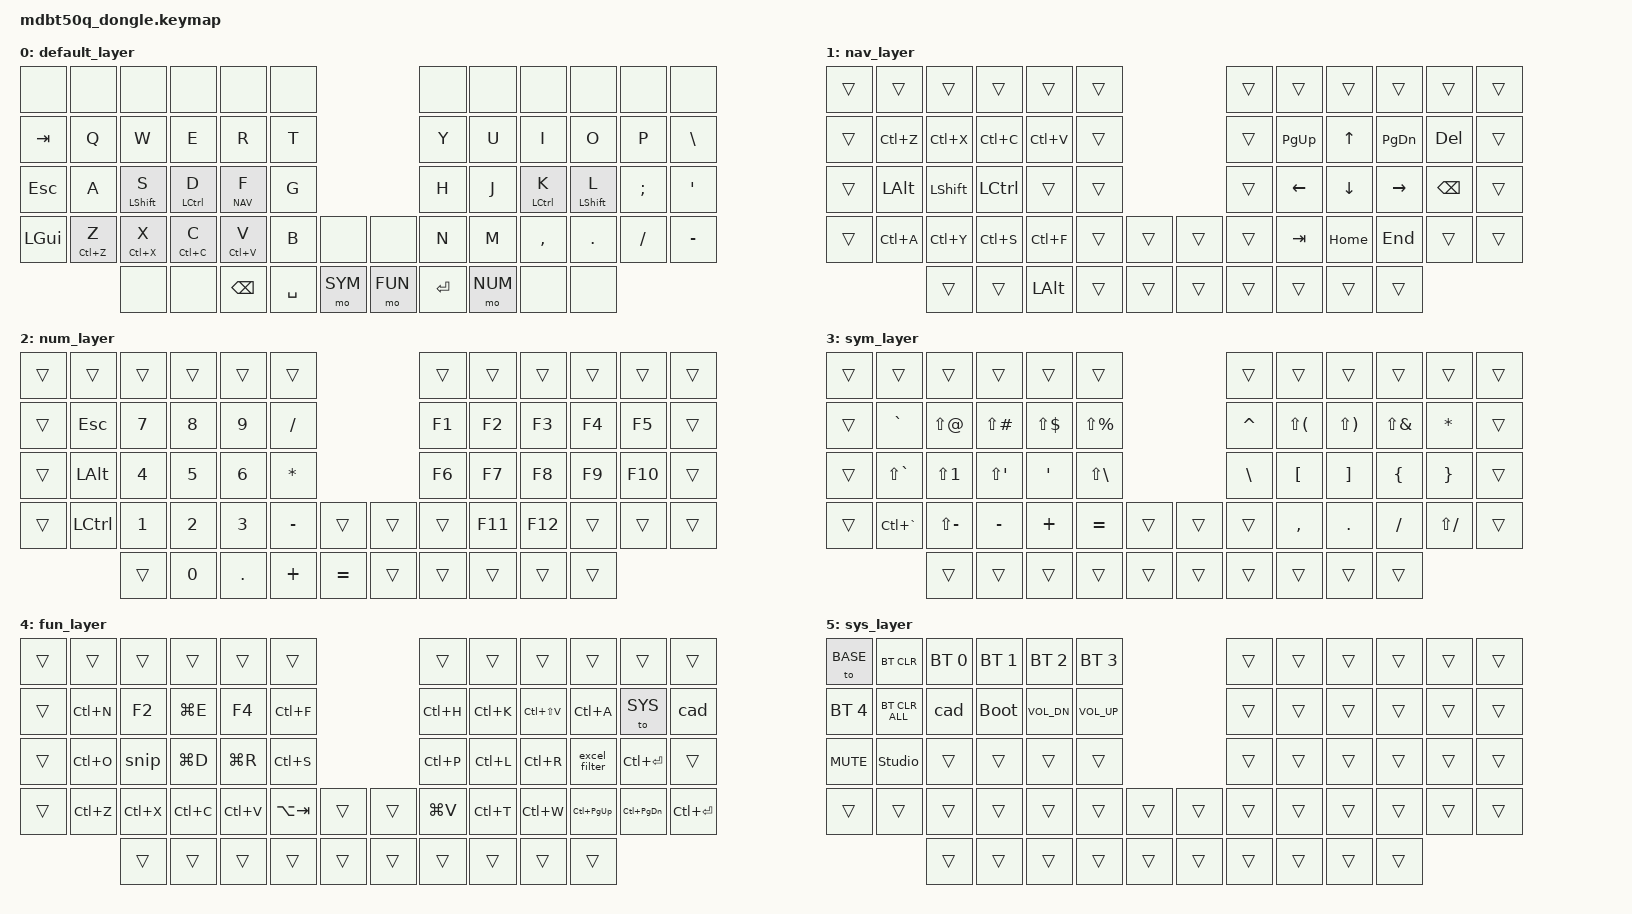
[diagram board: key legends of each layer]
#include <behaviors.dtsi>
#include <dt-bindings/zmk/bt.h>
#include <dt-bindings/zmk/keys.h>

#define BASE 0
#define NAV  1
#define NUM  2
#define SYM  3
#define FUN  4
#define SYS  5

&lt {
    tapping-term-ms = <200>;
};

/ {
    macros {
        snip: snip {
            compatible = "zmk,behavior-macro";
            #binding-cells = <0>;
            bindings = <&macro_tap &kp LG(LS(S))>;
            label = "SNIP";
        };

        excel_filter: excel_filter {
            compatible = "zmk,behavior-macro";
            #binding-cells = <0>;
            bindings = <&macro_tap &kp LC(LS(L))>;
            label = "EXCEL_FILTER";
        };

        cad: ctrl_alt_delete {
            compatible = "zmk,behavior-macro";
            #binding-cells = <0>;
            bindings
                = <&macro_press &kp LCTRL &kp LALT>
                , <&macro_tap &kp DELETE>
                , <&macro_release &kp LALT &kp LCTRL>
                ;
            label = "CAD";
        };
    };

    combos {
        compatible = "zmk,combos";

        find {
            bindings = <&kp LC(F)>;
            key-positions = <28 29>;
        };
    };

    behaviors {
        hm: homerow_mods {
            compatible = "zmk,behavior-hold-tap";
            #binding-cells = <2>;
            flavor = "tap-preferred";
            tapping-term-ms = <150>;
            quick-tap-ms = <0>;
            bindings = <&kp>, <&kp>;
        };
    };

    keymap {
        compatible = "zmk,keymap";

        default_layer {
            bindings = <
&none        &none        &none           &none          &none          &none                            &none           &none       &none        &none            &none           &none
&kp TAB      &kp Q        &kp W           &kp E          &kp R          &kp T                           &kp Y           &kp U       &kp I        &kp O            &kp P           &kp BACKSLASH
&kp ESCAPE   &kp A        &hm LSHFT S     &hm LCTRL D    &lt NAV F      &kp G                           &kp H           &kp J      &hm LCTRL K  &hm LSHFT L      &kp SEMICOLON   &kp SQT
&kp LGUI     &hm LC(Z) Z  &hm LC(X) X     &hm LC(C) C    &hm LC(V) V    &kp B       &none        &none    &kp N           &kp M       &kp COMMA    &kp DOT          &kp FSLH        &kp MINUS
                           &none          &none          &kp BACKSPACE  &kp SPACE   &mo SYM      &mo FUN  &kp RET         &mo NUM     &none        &none
            >;
        };

        nav_layer {
            bindings = <
&trans       &trans       &trans          &trans         &trans         &trans                           &trans          &trans      &trans       &trans           &trans          &trans
&trans       &kp LC(Z)    &kp LC(X)       &kp LC(C)      &kp LC(V)      &trans                           &trans          &kp PG_UP   &kp UP       &kp PG_DN        &kp DELETE     &trans
&trans       &kp LALT     &kp LSHFT       &kp LCTRL      &trans         &trans                           &trans          &kp LEFT    &kp DOWN     &kp RIGHT        &kp BACKSPACE  &trans
&trans       &kp LC(A)    &kp LC(Y)       &kp LC(S)      &kp LC(F)      &trans      &trans       &trans    &trans          &kp TAB     &kp HOME     &kp END          &trans          &trans
                           &trans         &trans         &kp LEFT_ALT   &trans      &trans       &trans    &trans          &trans      &trans       &trans
            >;
        };

        num_layer {
            bindings = <
&trans       &trans       &trans          &trans         &trans         &trans                           &trans          &trans      &trans       &trans           &trans          &trans
&trans       &kp ESC      &kp N7          &kp N8         &kp N9        &kp FSLH                         &kp F1          &kp F2      &kp F3       &kp F4           &kp F5         &trans
&trans       &kp LALT     &kp N4          &kp N5         &kp N6        &kp STAR                         &kp F6          &kp F7      &kp F8       &kp F9           &kp F10        &trans
&trans       &kp LCTRL    &kp N1          &kp N2         &kp N3        &kp MINUS    &trans      &trans    &trans          &kp F11     &kp F12      &trans           &trans          &trans
                           &trans         &kp N0         &kp DOT       &kp PLUS    &kp EQUAL    &trans    &trans          &trans      &trans       &trans
            >;
        };

        sym_layer {
            bindings = <
&trans       &trans       &trans          &trans         &trans         &trans                           &trans          &trans      &trans       &trans           &trans          &trans
&trans       &kp GRAVE    &kp LS(AT)      &kp LS(POUND)  &kp LS(DLLR)   &kp LS(PRCNT)                    &kp CARET       &kp LS(LPAR) &kp LS(RPAR)  &kp LS(AMPERSAND) &kp STAR      &trans
&trans       &kp LS(GRAVE)&kp LS(N1)      &kp LS(SQT)    &kp SQT        &kp LS(BSLH)                     &kp BSLH        &kp LBKT    &kp RBKT     &kp LBRC         &kp RBRC       &trans
&trans       &kp LC(GRAVE)&kp LS(MINUS)   &kp MINUS      &kp PLUS       &kp EQUAL    &trans      &trans    &trans          &kp COMMA   &kp DOT      &kp FSLH         &kp LS(FSLH)   &trans
                           &trans         &trans         &trans         &trans      &trans       &trans    &trans          &trans      &trans       &trans
            >;
        };

        fun_layer {
            bindings = <
&trans       &trans       &trans          &trans         &trans         &trans                           &trans          &trans      &trans       &trans           &trans          &trans
&trans       &kp LC(N)    &kp F2          &kp LG(E)      &kp F4         &kp LC(F)                       &kp LC(H)       &kp LC(K)   &kp LC(LS(V)) &kp LC(A)        &to SYS       &cad
&trans       &kp LC(O)    &snip           &kp LG(D)      &kp LG(R)      &kp LC(S)                       &kp LC(P)       &kp LC(L)   &kp LC(R)     &excel_filter    &kp LC(RET)    &trans
&trans       &kp LC(Z)    &kp LC(X)       &kp LC(C)      &kp LC(V)      &kp LA(TAB)  &trans     &trans    &kp LG(V)      &kp LC(T)   &kp LC(W)    &kp LC(PG_UP)   &kp LC(PG_DN)  &kp LC(RET)
                           &trans         &trans         &trans         &trans      &trans       &trans    &trans          &trans      &trans       &trans
            >;
        };

        sys_layer {
            bindings = <
&to BASE     &bt BT_CLR   &bt BT_SEL 0    &bt BT_SEL 1   &bt BT_SEL 2   &bt BT_SEL 3                     &trans          &trans      &trans       &trans           &trans          &trans
&bt BT_SEL 4 &bt BT_CLR_ALL &cad          &bootloader    &kp C_VOL_DN   &kp C_VOL_UP                    &trans          &trans      &trans       &trans           &trans          &trans
&kp C_MUTE   &studio_unlock    &trans          &trans         &trans         &trans                           &trans          &trans      &trans       &trans           &trans          &trans
&trans       &trans            &trans          &trans         &trans         &trans      &trans       &trans    &trans          &trans      &trans       &trans           &trans          &trans
                               &trans         &trans         &trans         &trans      &trans       &trans    &trans          &trans      &trans       &trans
            >;
        };
    };
};
